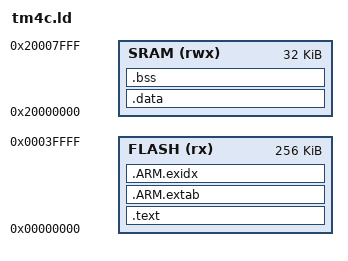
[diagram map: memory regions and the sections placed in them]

MEMORY
{
    FLASH (rx) : ORIGIN = 0x00000000, LENGTH = 0x00040000
    SRAM (rwx) : ORIGIN = 0x20000000, LENGTH = 0x00008000
}

SECTIONS
{
    .text :
    {
        _text = .;
        KEEP(*(.isr_vector))
        *(.text*)
        *(.rodata*)
        KEEP (*(.init))
        KEEP (*(.fini))
        _etext = .;
    } > FLASH

    /* ARM exception unwinding sections */
    .ARM.extab :
    {
        *(.ARM.extab* .gnu.linkonce.armextab.*)
    } > FLASH

    .ARM.exidx :
    {
        __exidx_start = .;
        *(.ARM.exidx* .gnu.linkonce.armexidx.*)
        __exidx_end = .;
    } > FLASH

    _etext_all = .;

    .data : AT(_etext_all)
    {
        _data = .;
        _ldata = LOADADDR (.data);
        *(vtable)
        *(.data*)
        _edata = .;
    } > SRAM

    .bss :
    {
        _bss = .;
        *(.bss*)
        *(COMMON)
        _ebss = .;
    } > SRAM

    /* Heap starts after BSS - needed by sbrk */
    end = .;
    _end = .;
}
